# MIMXRT1011 register map
Vendor: nxp.com; File version: 1.0
CPU: CM7 r0p1, little endian, MPU, FPU, VTOR, 4 interrupt priority bits
Registers are 32-bit, read-write, reset 0x0 unless marked. A register's access mark holds for its fields unless they carry their own. Offsets are from the block's base; [hi:lo] are bit positions; lines under a group give offsets from that group; {n}, {i} and the like mark numbered series.

## OTFAD
Base 0x400A0000; alternate view of FLEXSPI
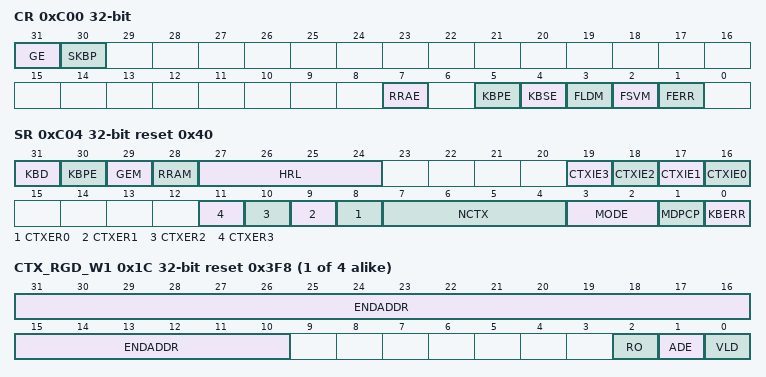
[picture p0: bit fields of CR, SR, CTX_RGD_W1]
0xC00 CR — Control Register
  [31] GE — Global OTFAD Enable
    0=DISABLE (OTFAD has decryption disabled. All data fetched by the FlexSPI bypasses OTFAD processing.); 1=ENABLE (OTFAD has decryption enabled, and processes data fetched by the FlexSPI as defined by the hardware configuration.)
  [30] SKBP — Start key blob processing
    0=NO_EFFECT (Key blob processing is not initiated.); 1=INIT_KB (Properly-enabled key blob processing is initiated.)
  [7] RRAE — Restricted Register Access Enable
    0=NORMAL (Register access is fully enabled. The OTFAD programming model registers can be accessed "normally".); 1=RESTRICT (Register access is restricted and only the CR, SR and optional MDPC registers can be accessed; others are treated as RAZ/WI.)
  [5] KBPE — Key Blob Processing Enable
    0=DISABLE (Key blob processing is disabled.); 1=ENABLE (Key blob processing is enabled.)
  [4] KBSE — Key Blob Scramble Enable
    0=DISABLE (Key blob KEK scrambling is disabled.); 1=ENABLE (Key blob KEK scrambling is enabled.)
  [3] FLDM — Force Logically Disabled Mode
    0=NO_EFFECT (No effect on the operating mode.); 1=FORCE_LDM (Force entry into LDM after a write with this data bit set. SR[MODE] signals the operating mode.)
  [2] FSVM — Force Security Violation Mode
    0=NO_EFFECT (No effect on the operating mode.); 1=FORCE_SVM (Force entry into SVM after a write with this data bit set and the data bit associated with FLDM cleared. SR[MODE] signals the operating mode.)
  [1] FERR — Force Error
    0=NO_EFFECT (No effect on the SR[KBERE] indicator.); 1=FORCE_ERROR (SR[KBERR] is immediately set after a write with this data bit set.)
0xC04 SR reset 0x40 — Status Register
  [31] KBD ro — Key Blob Processing Done
    0=NOT_DONE (Key blob processing was not enabled, or is not complete.); 1=DONE (Key blob processing was enabled and is complete.)
  [30] KBPE ro — Key Blob Processing Enable
    0=DISABLED (Key blob processing is not enabled.); 1=ENABLED (Key blob processing is enabled.)
  [29] GEM ro — Global Enable Mode
    0=DISABLED (OTFAD is disabled. All data fetched by the FlexSPI bypasses OTFAD processing.); 1=ENABLED (OTFAD is enabled, and processes data fetched by the FlexSPI as defined by the hardware configuration.)
  [28] RRAM ro — Restricted Register Access Mode
    0=NORMAL (Register access is fully enabled. The OTFAD programming model registers can be accessed "normally".); 1=RESTRICTED (Register access is restricted and only the CR, SR and optional MDPC registers can be accessed; others are treated as RAZ/WI.)
  [27:24] HRL ro — Hardware Revision Level
  [n+16] CTXIE{n} ro (n=0..3) — Context Integrity Error
    0=NOINTEGRITYERR (No key blob integrity error was detected for context "n".); 1=INTEGRITYERR (A key blob integrity error was detected in context "n".)
  [n+8] CTXER{n} ro (n=0..3) — Context Error
    0=NOERROR (No key blob error was detected for context "n".); 1=ERROR (A key blob integrity error might have been detected in context "n".)
  [7:4] NCTX ro — Number of Contexts
  [3:2] MODE ro — Operating Mode
    0=NORMAL (Operating in Normal mode (NRM)); 2=RES_10_SVM (Operating in Security Violation Mode (SVM)); 3=LDM (Operating in Logically Disabled Mode (LDM))
  [1] MDPCP ro — MDPC Present
  [0] KBERR write-1-clears — Key Blob Error
    0=NO_KB_ERR (No key blob error detected.); 1=KB_ERR (One or more key blob errors has been detected.)
{0xD00+0x40*i} CTX[{i}] (i=0..3) group
  {0x0+4j} CTX_KEY{j} (j=0..3) — AES Key Word
    [31:0] KEY — AES Key
  {0x10+4j} CTX_CTR{j} (j=0..1) — AES Counter Word
    [31:0] CTR — AES Counter
  0x18 CTX_RGD_W0 — AES Region Descriptor Word0
    [31:10] SRTADDR — Start Address
  0x1C CTX_RGD_W1 reset 0x3F8 — AES Region Descriptor Word1
    [31:10] ENDADDR — End Address
    [2] RO — Read-Only
      0=NORMAL (The context registers can be accessed normally (as defined by SR[RRAM]).); 1=RESTRICT (The context registers are read-only and accesses may be further restricted based on SR[RRAM].)
    [1] ADE — AES Decryption Enable.
      0=BYPASS (Bypass the fetched data.); 1=DECRYPT (Perform the CTR-AES128 mode decryption on the fetched data.)
    [0] VLD — Valid
      0=NOT_VALID (Context is invalid.); 1=VALID (Context is valid.)
